# MAX32550 register map
Vendor: Maxim Integrated; File version: 1.0
32-bit ARM Cortex-M3 microcontroller, 1MB of flash, 256KB of system RAM, 4KB of One-Time-Programmable (OTP) memory, 64KB of Boot ROM, 8KB of battery-backed and AES self-encrypted SRAM.
Registers are 32-bit, read-write, reset 0x0 unless marked. A register's access mark holds for its fields unless they carry their own. Offsets are from the block's base; lines under a group give offsets from that group; [hi:lo] are bit positions; {n}, {i} and the like mark numbered series; 'fields as' and 'values as' point back to an identical list; <NAME> marks a mode.

## Memory map
0x40000000 GlobalControl size 0x400 — Registers controlling global functions
0x40000400 SystemInitialization size 0x400 — System Initialization Registers
0x40001000 CryptographicAccelerator size 0x1000 — The cryptographic accelerator used to assist the computationally intensive operations of several common algorithms.
0x40003000 WatchdogTimer size 0x1000
0x40004000 SecurityMonitor size 0x1000 — The Security Monitor block used to monitor system threat conditions
0x40006000 RealTimeClock size 0x1000 — Real Time Clock and Alarm
0x40008000 GPIO_0 size 0x1000 — Individual I/O for Port 0
0x40009000 GPIO_1 size 0x1000 — Individual I/O for Port 1
0x4000A000 GPIO_2 size 0x1000 — Individual I/O for Port 2
0x4000C000 I2C size 0x1000 — Inter-Integrated Circuit
0x40010000 Timer_0 size 0x1000 — 32-bit reloadable timer that can be used for timing and event counting.
0x40011000 Timer_1 size 0x1000 — 32-bit reloadable timer that can be used for timing and event counting.
0x40012000 Timer_2 size 0x1000 — 32-bit reloadable timer that can be used for timing and event counting.
0x40013000 Timer_3 size 0x1000 — 32-bit reloadable timer that can be used for timing and event counting.
0x40014000 Timer_4 size 0x1000 — 32-bit reloadable timer that can be used for timing and event counting.
0x40015000 Timer_5 size 0x1000 — 32-bit reloadable timer that can be used for timing and event counting.
0x40018000 SPI0 size 0x1000 — Serial Peripheral Interface
0x40019000 SPI1 size 0x1000 — Serial Peripheral Interface
0x4001A000 SPI2 size 0x1000 — Serial Peripheral Interface
0x40020000 UART0 size 0x1000 — UART0 (Serial Port 0)
0x40021000 UART1 size 0x1000 — UART1 (Serial Port 1)
0x40028000 DMAController size 0x1000 — Fully programmable, chaining capable DMA channels
0x40029000 FlashController size 0x1000 — Flash Memory Control
0x4002A000 InstructionCacheController size 0x1000 — Registers to control the instruction cache
0x4002B000 MagneticStripeReader size 0x1000
0x4002C000 SmartCard size 0x1000 — LCD Clock Register
0x40030000 MonoLCDController size 0x1000 — LCD Interface
0x40031000 TFTController size 0x1000 — Color LCD Controller
0x40032000 SecureKeyboard size 0x1000
0x40034000 ADC size 0x1000 — Analog to Digital Converter
0x40038000 DAC size 0x1000 — Digital to Analog Converter
0x400B0000 USB size 0x1000 — Universal Serial Bus
0x400B5000 TrueRandomNumberGenerator size 0x1000 — Random Number Generator

## Interrupts
1 Watchdog_Timer (WatchdogTimer)
2 USB
3 RTC (RealTimeClock)
4 TRNG (TrueRandomNumberGenerator)
5 Timer0 (Timer_0)
6 Timer1 (Timer_1)
7 Timer2 (Timer_2)
8 Timer3 (Timer_3)
9 Timer4 (Timer_4)
10 Timer5 (Timer_5)
11 Smart_Card (SmartCard)
12 LCD_TFT (MonoLCDController)
13 I2C
14 UART0
15 UART1
16 SPI0
17 SPI1
18 SPI2
19 Secure_Keypad (SecureKeyboard)
20 ADC
21 DAC
22 MSR (MagneticStripeReader)
23 Flash_Controller (FlashController)
24 GPIO0 (GPIO_0)
25 GPIO1 (GPIO_1)
26 GPIO2 (GPIO_2)
27 Crypto_Engine (CryptographicAccelerator)
28 DMA0 (DMAController)
29 DMA1 (DMAController)
30 DMA2 (DMAController)
31 DMA3 (DMAController)

## SystemInitialization — System Initialization Registers
Base 0x40000400
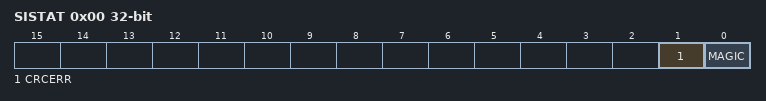
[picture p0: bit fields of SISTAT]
0x00 SISTAT ro — System Initialization Status Register
  [1] CRCERR — CRC Error Status. This bit is set by the system initialization block following power-up.
    on read: 0=noError (No CRC errors occurred during the read of the OTP memory block.); 1=error (A CRC error occurred while reading the OTP. The address of the failure location in the OTP memory is stored in the ERRADDR register.)
  [0] MAGIC — Magic Word Validation. This bit is set by the system initialization block following power-up.
    on read: 0=magicNotSet (Magic word was not set (OTP has not been initialized properly).); 1=magicSet (Magic word was set (OTP contains valid settings).)
0x04 ERRADDR ro — Read-only field set by the SIB block if a CRC error occurs during the read of the OTP memory. Contains the failing address in OTP memory (when CRCERR equals 1).
